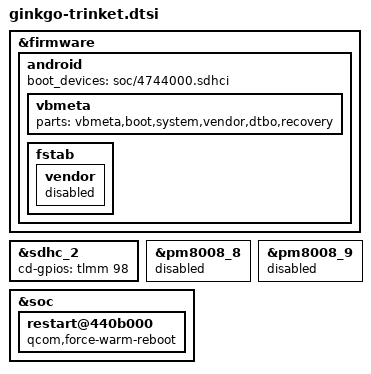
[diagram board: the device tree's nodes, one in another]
/*
 * Copyright (c) 2019, The Linux Foundation. All rights reserved.
 * Copyright (C) 2021 XiaoMi, Inc.
 *
 * This program is free software; you can redistribute it and/or modify
 * it under the terms of the GNU General Public License version 2 and
 * only version 2 as published by the Free Software Foundation.
 *
 * This program is distributed in the hope that it will be useful,
 * but WITHOUT ANY WARRANTY; without even the implied warranty of
 * MERCHANTABILITY or FITNESS FOR A PARTICULAR PURPOSE.  See the
 * GNU General Public License for more details.
 */

#include "../trinket-idp.dtsi"
#include "ginkgo-trinket-audio.dtsi"
#include "ginkgo-trinket-battery.dtsi"
#include "ginkgo-trinket-camera.dtsi"
#include "ginkgo-trinket-display.dtsi"
#include "ginkgo-trinket-fingerprint.dtsi"
#include "ginkgo-trinket-ir.dtsi"
#include "ginkgo-trinket-led.dtsi"
#include "ginkgo-trinket-memory.dtsi"
#include "ginkgo-trinket-nfc.dtsi"
#include "ginkgo-trinket-pinctrl.dtsi"
#include "ginkgo-trinket-pm6125.dtsi"
#include "ginkgo-trinket-regulator.dtsi"
#include "ginkgo-trinket-thermal.dtsi"
#include "ginkgo-trinket-touchpad.dtsi"
#include "ginkgo-trinket-usb.dtsi"
#include "ginkgo-trinket-vibrator.dtsi"

&firmware {
	android {
		boot_devices = "soc/4744000.sdhci";
		vbmeta {
			parts = "vbmeta,boot,system,vendor,dtbo,recovery";
		};

		fstab {
			vendor {
				status = "disabled";
			};
		};
	};
};

&sdhc_2 {
	cd-gpios = <&tlmm 98 0>;
};

&pm8008_8 {
	status = "disabled";
};

&pm8008_9 {
	status = "disabled";
};

&soc {
	restart@440b000 {
		qcom,force-warm-reboot;
	};
};
